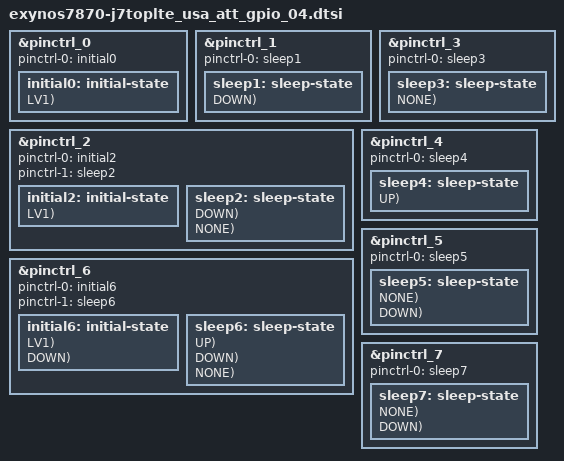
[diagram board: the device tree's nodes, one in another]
/*
 * Copyright (c) 2015 Samsung Electronics Co., Ltd.
 *		http://www.samsung.com
 *
 * This program is free software; you can redistribute it and/or modify
 * it under the terms of the GNU General Public License version 2 as
 * published by the Free Software Foundation.
 */

#include "exynos_gpio_config_macros.dtsi"

/* 0x139F_0000(ALIVE): gpa0~2, gpq0 */
&pinctrl_0 {
	pinctrl-names = "default";
	pinctrl-0 = <&initial0>;
	initial0: initial-state {
		PIN_IN(etc0-1, DOWN, LV1);	/* NC */
		PIN_IN(etc0-3, DOWN, LV1);	/* NC */
		PIN_IN(gpa0-5, NONE, LV1);	/* PROX_INT */
		PIN_IN(gpa1-5, DOWN, LV1);	/* NC */

		PIN_IN(gpq0-1, DOWN, LV1);	/* NC */
	};

	/*
	 * Note:
	 *   Please do not make "sleep-state" node for GPA group GPIOs.
	 *   GPA group doesn't have power-down status.
	 */
};

/* 0x148C_0000(DISPAUD): gpz0~2 */
&pinctrl_1 {
	pinctrl-names = "sleep";
	pinctrl-0 = <&sleep1>;

	sleep1: sleep-state {
		PIN_SLP(gpz0-0, INPUT, DOWN);	/* BT_PCM_SYNC */
		PIN_SLP(gpz0-1, INPUT, DOWN);	/* BT_PCM_CLK */
		PIN_SLP(gpz0-2, INPUT, DOWN);	/* BT_PCM_D_OUT */
		PIN_SLP(gpz0-3, INPUT, DOWN);	/* BT_PCM_D_IN */

		PIN_SLP(gpz1-0, INPUT, DOWN);	/* BB_I2S_LRCK */
		PIN_SLP(gpz1-1, INPUT, DOWN);	/* AMP_I2S_BCLK */
		PIN_SLP(gpz1-2, INPUT, DOWN);	/* BB_I2S_DI */
		PIN_SLP(gpz1-3, INPUT, DOWN);	/* BB_I2S_DO */
		PIN_SLP(gpz1-5, INPUT, DOWN);	/* AMP_I2S_D_IN */

		PIN_SLP(gpz2-0, INPUT, DOWN);	/* NC */
		PIN_SLP(gpz2-1, INPUT, DOWN);	/* NC */
		PIN_SLP(gpz2-2, INPUT, DOWN);	/* NC */
		PIN_SLP(gpz2-3, INPUT, DOWN);	/* NC */
	};
};

/* 0x139E_0000(FP): gpc7 */
&pinctrl_2 {
	pinctrl-names = "default","sleep";
	pinctrl-0 = <&initial2>;
	pinctrl-1 = <&sleep2>;
	initial2: initial-state {
		PIN_IN(gpc7-0, DOWN, LV1);	/* NC */
		PIN_IN(gpc7-1, DOWN, LV1);	/* NC */
		PIN_IN(gpc7-2, DOWN, LV1);	/* NC */
		PIN_IN(gpc7-3, DOWN, LV1);	/* NC */
	};
	sleep2: sleep-state {
		PIN_SLP(gpc7-0, INPUT, DOWN);	/* NC */
		PIN_SLP(gpc7-1, INPUT, DOWN);	/* NC */
		PIN_SLP(gpc7-2, INPUT, DOWN);	/* NC */
		PIN_SLP(gpc7-3, INPUT, DOWN);	/* NC */
		PIN_SLP(gpc7-4, PREV, NONE);	/* SENSOR_LDO_EN */
	};
};

/* 0x1375_0000(FSYS): gpr0~4 */
/* pinctrl_3 */
&pinctrl_3 {
	pinctrl-names = "sleep";
	pinctrl-0 = <&sleep3>;
	sleep3: sleep-state {
		PIN_SLP(gpr0-1, OUT1, NONE);	/* EMMC_CMD */
		PIN_SLP(gpr2-1, OUT0, NONE);	/* WLAN_CMD */
	};
};


/* 0x1053_0000(MIF): gpm0 */
&pinctrl_4 {
	pinctrl-names = "sleep";
	pinctrl-0 = <&sleep4>;
	sleep4: sleep-state {
		PIN_SLP(gpm0-0, PREV, UP);	/* PMIC_SDA_1P8 */
		PIN_SLP(gpm0-1, PREV, UP);	/* PMIC_SCL_1P8 */
	};
};

/* 0x139C_0000(NFC): gpc2 */
&pinctrl_5 {
	pinctrl-names = "sleep";
	pinctrl-0 = <&sleep5>;
	sleep5: sleep-state {
		PIN_SLP(gpc2-0, INPUT, NONE);	/* TSP_SDA */
		PIN_SLP(gpc2-1, INPUT, NONE);	/* TSP_SCL */
		PIN_SLP(gpc2-2, INPUT, DOWN);	/* NC */
		PIN_SLP(gpc2-3, INPUT, DOWN);	/* NC */
	};
};

/* 0x139B_0000(TOP): gpb0, gpc0~1, gpc4~6, gpc8~9, gpd1~4, gpe0, gpf0~4 */
&pinctrl_6 {
	pinctrl-names = "default","sleep";
	pinctrl-0 = <&initial6>;
	pinctrl-1 = <&sleep6>;
	initial6: initial-state {
		PIN_IN(gpc0-2, DOWN, LV1);	/* NC  */

		PIN_OUT_SET_PULL(gpd1-1, 0, LV1, DOWN);	/* CAM_AF_2P8_EN */
		PIN_IN(gpd1-3, NONE, LV1);	/* GRIP_DET  */
		PIN_IN(gpd1-5, DOWN, LV1);	/* NC */
		PIN_OUT_SET_PULL(gpd1-6, 0, LV1, DOWN);	/* VTCAM_CORE_EN */

		PIN_IN(gpd2-4, NONE, LV1);	/* HW_REV0 */
		PIN_IN(gpd2-5, NONE, LV1);	/* HW_REV1 */

		PIN_IN(gpd3-0, NONE, LV1);	/* HW_REV2 */
		PIN_IN(gpd3-1, NONE, LV1);	/* HW_REV3 */
		PIN_OUT_SET_PULL(gpd3-2, 0, LV1, DOWN);	/* CAM_FLASH_EN */
		PIN_OUT_SET_PULL(gpd3-3, 0, LV1, DOWN);	/* CAM_TORCH_EN */

		PIN_OUT_SET(gpd4-4, 0, LV1);	/* CAM_SENSOR_CORE_EN */
		PIN_IN(gpd4-5, DOWN, LV1);	/* NC*/
		PIN_OUT_SET(gpd4-6, 1, LV1);	/* IF_PMIC_RST */

		PIN_OUT_SET_PULL(gpf3-1, 0, LV1, DOWN);	/* VTCAM_RST_N */
		PIN_OUT_SET_PULL(gpf3-3, 0, LV1, DOWN);	/* CAM_RST */

		PIN_IN(gpf4-1, DOWN, LV1);	/* NC*/
	};
	sleep6: sleep-state {
		PIN_SLP(gpb0-0, INPUT, UP);	/* BT_UART_RXD */
		PIN_SLP(gpb0-1, OUT1, UP);	/* BT_UART_TXD */
		PIN_SLP(gpb0-2, INPUT, UP);	/* BT_UART_CTS */
		PIN_SLP(gpb0-3, OUT1, UP);	/* BT_UART_RTS */

		PIN_SLP(gpc0-1, INPUT, DOWN);	/* NC */
		PIN_SLP(gpc0-2, INPUT, DOWN);	/* NC */

		PIN_SLP(gpc1-0, PREV, UP);	/* IF_PMIC_SDA_1P8 */
		PIN_SLP(gpc1-1, PREV, UP);	/* IF_PMIC_SCL_1P8 */
		PIN_SLP(gpc1-2, INPUT, DOWN);	/* NC */
		PIN_SLP(gpc1-3, INPUT, DOWN);	/* NC */

		PIN_SLP(gpc4-0, INPUT, NONE);	/* FG_SDA_1P8 */
		PIN_SLP(gpc4-1, INPUT, NONE);	/* FG_SCL_1P8 */
		PIN_SLP(gpc4-2, INPUT, NONE);	/* SENSOR_SDA_1P8 */
		PIN_SLP(gpc4-3, INPUT, NONE);	/* SENSOR_SCL_1P8 */

		PIN_SLP(gpc5-0, INPUT, NONE);	/* AMP_SDA_1P8 */
		PIN_SLP(gpc5-1, INPUT, NONE);	/* AMP_SCL_1P8 */

		PIN_SLP(gpc6-0, INPUT, DOWN);	/* ESE_SPI_CLK */
		PIN_SLP(gpc6-1, INPUT, DOWN);	/* NC */
		PIN_SLP(gpc6-2, INPUT, DOWN);	/* ESE_SPI_MISO */
		PIN_SLP(gpc6-3, INPUT, DOWN);	/* ESE_SPI_MOSI */

		PIN_SLP(gpc8-0, INPUT, NONE);	/* TOUCH_SDA_1P8 */
		PIN_SLP(gpc8-1, INPUT, NONE);	/* TOUCH_SCL_1P8 */

		PIN_SLP(gpc9-0, INPUT, NONE);	/* LCD_BL_SDA_1P8 */
		PIN_SLP(gpc9-1, INPUT, NONE);	/* LCD_BL_SCL_1P8 */

		PIN_SLP(gpd1-0, PREV, NONE);	/* WRSTB_IN */
		PIN_SLP(gpd1-1, OUT0, DOWN);	/* CAM_AF_2P8_EN */
		PIN_SLP(gpd1-2, PREV, NONE);	/* PANEL_ENP */
		PIN_SLP(gpd1-3, INPUT, NONE);	/* GRIP_DET */
		PIN_SLP(gpd1-4, PREV, NONE);	/* PANEL_ENN */
		PIN_SLP(gpd1-5, INPUT, DOWN);	/* NC */
		PIN_SLP(gpd1-6, OUT0, DOWN);	/* VTCAM_CORE_EN */

		PIN_SLP(gpd2-0, INPUT, DOWN);	/* LCD_BC_CTRL */
		PIN_SLP(gpd2-1, INPUT, DOWN);	/* LCD_GPIO0 */
		PIN_SLP(gpd2-2, INPUT, DOWN);	/* NC */
		PIN_SLP(gpd2-3, INPUT, DOWN);	/* NC */
		PIN_SLP(gpd2-4, INPUT, NONE);	/* HW_REV0 */
		PIN_SLP(gpd2-5, INPUT, NONE);	/* HW_REV1 */

		PIN_SLP(gpd3-0, INPUT, NONE);	/* HW_REV2 */
		PIN_SLP(gpd3-1, INPUT, NONE);	/* HW_REV3 */
		PIN_SLP(gpd3-2, OUT0, DOWN);	/* CAM_FLASH_EN */
		PIN_SLP(gpd3-3, PREV, NONE);	/* CAM_TORCH_EN */
		PIN_SLP(gpd3-4, PREV, NONE);	/* MLCD_RST */
		PIN_SLP(gpd3-5, OUT0, DOWN);	/* CAM_MAIN_2P8_EN */
		PIN_SLP(gpd3-6, PREV, NONE);	/* WLAN_EN */
		PIN_SLP(gpd3-7, PREV, NONE);	/* PANEL_EN_P */

		PIN_SLP(gpd4-0, PREV, NONE);	/* BT_EN */
		PIN_SLP(gpd4-1, INPUT, DOWN);	/* NC */
		PIN_SLP(gpd4-2, PREV, NONE);	/* AMP_RST_N */
		PIN_SLP(gpd4-3, PREV, NONE);	/* LCD_BL_EN */
		PIN_SLP(gpd4-4, OUT0, DOWN);	/* CAM_SENSOR_CORE_EN */
		PIN_SLP(gpd4-5, PREV, NONE);	/* PROXY_LED_EN */
		PIN_SLP(gpd4-6, PREV, NONE);	/* IF_PMIC_RST */

		PIN_SLP(gpe0-0, INPUT, DOWN);	/* CAM_MCLK */
		PIN_SLP(gpe0-1, INPUT, DOWN);	/* VTCAM_MCLK */
		PIN_SLP(gpe0-2, INPUT, DOWN);	/* TE(TP4039) */

		PIN_SLP(gpf0-0, INPUT, DOWN);	/* CAM_SDA_1P8 */
		PIN_SLP(gpf0-1, INPUT, DOWN);	/* CAM_SCL_1P8 */
		PIN_SLP(gpf0-2, INPUT, DOWN);	/* VTCAM_SDA_1P8 */
		PIN_SLP(gpf0-3, INPUT, DOWN);	/* VTCAM_SCL_1P8 */

		PIN_SLP(gpf1-0, INPUT, DOWN);	/* CAM_AF_EEP_SDA_1P8 */
		PIN_SLP(gpf1-1, INPUT, DOWN);	/* CAM_AF_EEP_SCL_1P8 */

		PIN_SLP(gpf2-0, INPUT, DOWN);	/* VTCAM_EEP_SDA_1P8 */
		PIN_SLP(gpf2-1, INPUT, DOWN);	/* VTCAM_EEP_SCL_1P8 */

		PIN_SLP(gpf3-0, INPUT, DOWN);	/* NC */
		PIN_SLP(gpf3-1, OUT0, DOWN);	/* VTCAM_RST_N */
		PIN_SLP(gpf3-2, OUT0, DOWN);	/* VDD_CAM_IO_1P8_EN */
		PIN_SLP(gpf3-3, INPUT, DOWN);	/* CAM_RST */

		PIN_SLP(gpf4-0, INPUT, DOWN);	/* NC */
		PIN_SLP(gpf4-1, INPUT, DOWN);	/* NC */
		PIN_SLP(gpf4-2, INPUT, DOWN);	/* NC */
		PIN_SLP(gpf4-3, INPUT, DOWN);	/* NC */
		PIN_SLP(gpf4-4, INPUT, DOWN);	/* NC */
	};
};

/* 0x139D_0000(ESE): gpc3 */
&pinctrl_7 {
	pinctrl-names = "sleep";
	pinctrl-0= <&sleep7>;
	sleep7: sleep-state {
		PIN_SLP(gpc3-0, INPUT, NONE);	/* PROXY_I2C_SDA */
		PIN_SLP(gpc3-1, INPUT, NONE);	/* PROXY_I2C_SCL */
		PIN_SLP(gpc3-2, INPUT, DOWN);	/* NC */
	};
};
